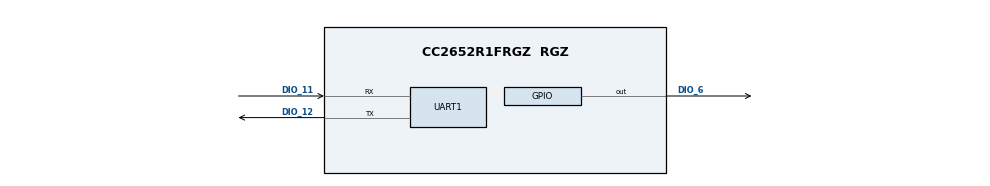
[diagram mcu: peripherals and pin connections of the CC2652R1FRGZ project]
/**
 * @cliArgs --device "CC2652R1FRGZ" --package "RGZ" --part "Default" --product "simplelink_cc13x2_26x2_sdk@4.30.00.54"
 * @versions {"data":"2020090214","timestamp":"2020090214","tool":"1.6.0+1543","templates":"2020090214"}
 */

/**
 * Import the modules used in this configuration.
 */
const GPIO  = scripting.addModule("/ti/drivers/GPIO");
const GPIO1 = GPIO.addInstance();
const RTOS  = scripting.addModule("/ti/drivers/RTOS");
const UART  = scripting.addModule("/ti/drivers/UART");
const UART1 = UART.addInstance();

/**
 * Write custom configuration values to the imported modules.
 */
GPIO1.mode              = "Output";
GPIO1.$name             = "CONFIG_GPIO_LED_0";
GPIO1.gpioPin.$assign   = "DIO_6";
GPIO1.pinInstance.$name = "CONFIG_PIN_0";

const CCFG              = scripting.addModule("/ti/devices/CCFG", {}, false);
CCFG.ccfgTemplate.$name = "ti_devices_CCFGTemplate0";

UART1.$name               = "CONFIG_UART_0";
UART1.uart.$assign        = "UART1";
UART1.uart.txPin.$assign  = "DIO_12";
UART1.uart.rxPin.$assign  = "DIO_11";
UART1.txPinInstance.$name = "CONFIG_PIN_1";
UART1.rxPinInstance.$name = "CONFIG_PIN_2";
